VERSION "MyDevice CAN Protocol"

NS_ :

BS_:

BU_: ECU

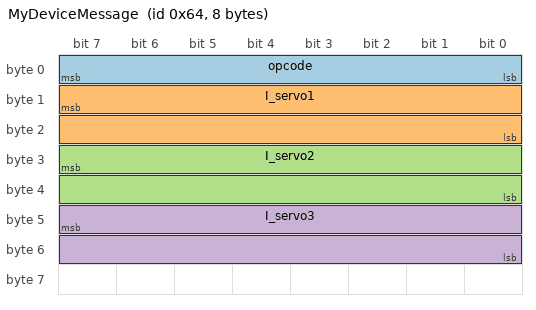
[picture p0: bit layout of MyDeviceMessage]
BO_ 100 MyDeviceMessage: 8 ECU
    SG_ opcode        : 0|8@1+ (1,0) [0|255] ""  ECU
    SG_ I_servo1      : 15|16@0+ (1,0) [0|65535] "mA" ECU
    SG_ I_servo2      : 31|16@0+ (1,0) [0|65535] "mA" ECU
    SG_ I_servo3      : 47|16@0+ (1,0) [0|65535] "mA" ECU
VAL_ 100 opcode 0x21 "CAN_CMD_GET_SERVO_CURRENT_1_3_ACK";
